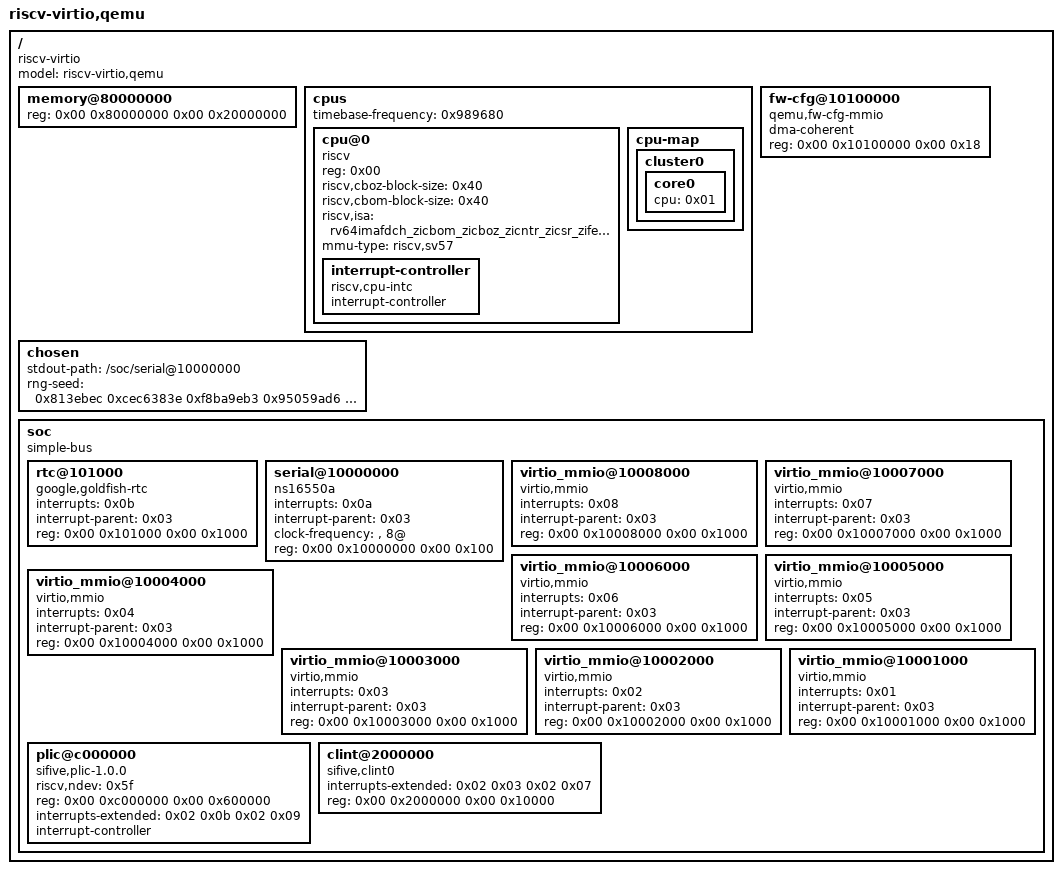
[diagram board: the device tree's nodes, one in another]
/dts-v1/;

/ {
	#address-cells = <0x02>;
	#size-cells = <0x02>;
	compatible = "riscv-virtio";
	model = "riscv-virtio,qemu";

	memory@80000000 {
		device_type = "memory";
		reg = <0x00 0x80000000 0x00 0x20000000>;
	};
	// reserved-memory {
	//     #address-cells = <2>;
	//     #size-cells = <2>;
	//     ranges;

	//     linux_kernel@80000000 {
	//         reg = <0x00 0x80000000 0x00 0x01000000>;
	//         no-map;
	//     };
	// };
	// memory@A0000000 {
	//     device_type = "memory";
	//     reg = <0x00 0xA0000000 0x00 0x20000000>;
	// };

	cpus {
		#address-cells = <0x01>;
		#size-cells = <0x00>;
		timebase-frequency = <0x989680>;

		cpu@0 {
			phandle = <0x01>;
			device_type = "cpu";
			reg = <0x00>;
			status = "okay";
			compatible = "riscv";
			riscv,cboz-block-size = <0x40>;
			riscv,cbom-block-size = <0x40>;
			riscv,isa = "rv64imafdch_zicbom_zicboz_zicntr_zicsr_zifencei_zihintntl_zihintpause_zihpm_zawrs_zfa_zca_zcd_zba_zbb_zbc_zbs_sstc_svadu";
			mmu-type = "riscv,sv57";

			interrupt-controller {
				#interrupt-cells = <0x01>;
				interrupt-controller;
				compatible = "riscv,cpu-intc";
				phandle = <0x02>;
			};
		};

		cpu-map {

			cluster0 {

				core0 {
					cpu = <0x01>;
				};
			};
		};
	};


	fw-cfg@10100000 {
		dma-coherent;
		reg = <0x00 0x10100000 0x00 0x18>;
		compatible = "qemu,fw-cfg-mmio";
	};


	chosen {
		stdout-path = "/soc/serial@10000000";
		rng-seed = <0x813ebec 0xcec6383e 0xf8ba9eb3 0x95059ad6 0x12d01a83 0x38fb6f6d 0x580003eb 0xe7e69d35>;
	};

	soc {
		#address-cells = <0x02>;
		#size-cells = <0x02>;
		compatible = "simple-bus";
		ranges;

		rtc@101000 {
			interrupts = <0x0b>;
			interrupt-parent = <0x03>;
			reg = <0x00 0x101000 0x00 0x1000>;
			compatible = "google,goldfish-rtc";
		};

		serial@10000000 {
			interrupts = <0x0a>;
			interrupt-parent = <0x03>;
			clock-frequency = "", "8@";
			reg = <0x00 0x10000000 0x00 0x100>;
			compatible = "ns16550a";
		};

		virtio_mmio@10008000 {
			interrupts = <0x08>;
			interrupt-parent = <0x03>;
			reg = <0x00 0x10008000 0x00 0x1000>;
			compatible = "virtio,mmio";
		};

		virtio_mmio@10007000 {
			interrupts = <0x07>;
			interrupt-parent = <0x03>;
			reg = <0x00 0x10007000 0x00 0x1000>;
			compatible = "virtio,mmio";
		};

		virtio_mmio@10006000 {
			interrupts = <0x06>;
			interrupt-parent = <0x03>;
			reg = <0x00 0x10006000 0x00 0x1000>;
			compatible = "virtio,mmio";
		};

		virtio_mmio@10005000 {
			interrupts = <0x05>;
			interrupt-parent = <0x03>;
			reg = <0x00 0x10005000 0x00 0x1000>;
			compatible = "virtio,mmio";
		};

		virtio_mmio@10004000 {
			interrupts = <0x04>;
			interrupt-parent = <0x03>;
			reg = <0x00 0x10004000 0x00 0x1000>;
			compatible = "virtio,mmio";
		};

		virtio_mmio@10003000 {
			interrupts = <0x03>;
			interrupt-parent = <0x03>;
			reg = <0x00 0x10003000 0x00 0x1000>;
			compatible = "virtio,mmio";
		};

		virtio_mmio@10002000 {
			interrupts = <0x02>;
			interrupt-parent = <0x03>;
			reg = <0x00 0x10002000 0x00 0x1000>;
			compatible = "virtio,mmio";
		};

		virtio_mmio@10001000 {
			interrupts = <0x01>;
			interrupt-parent = <0x03>;
			reg = <0x00 0x10001000 0x00 0x1000>;
			compatible = "virtio,mmio";
		};

		plic@c000000 {
			phandle = <0x03>;
			riscv,ndev = <0x5f>;
			reg = <0x00 0xc000000 0x00 0x600000>;
			interrupts-extended = <0x02 0x0b 0x02 0x09>;
			interrupt-controller;
			compatible = "sifive,plic-1.0.0", "riscv,plic0";
			#address-cells = <0x00>;
			#interrupt-cells = <0x01>;
		};

		clint@2000000 {
			interrupts-extended = <0x02 0x03 0x02 0x07>;
			reg = <0x00 0x2000000 0x00 0x10000>;
			compatible = "sifive,clint0", "riscv,clint0";
		};
	};
};
